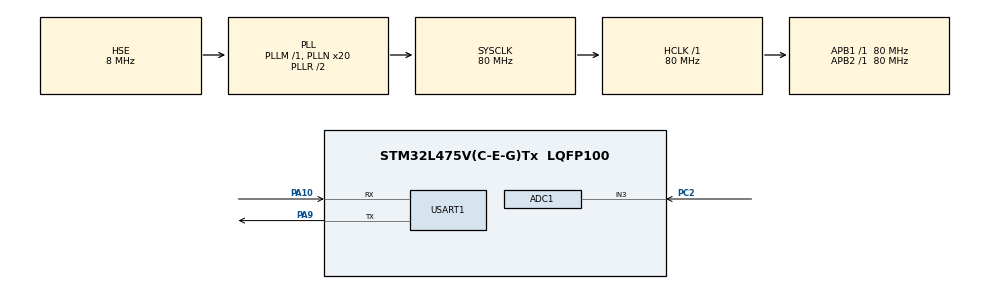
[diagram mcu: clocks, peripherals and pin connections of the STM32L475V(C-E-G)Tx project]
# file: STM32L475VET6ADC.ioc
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ADC1.Channel-1\#ChannelRegularConversion=ADC_CHANNEL_3
ADC1.ClockPrescaler=ADC_CLOCK_SYNC_PCLK_DIV2
ADC1.ContinuousConvMode=ENABLE
ADC1.EnableInjectedConversion=ENABLE
ADC1.InjMonitoredBy-2\#ChannelInjectedConversion=__NULL
ADC1.InjNumberOfConversion=1
ADC1.InjectedChannel-2\#ChannelInjectedConversion=ADC_CHANNEL_3
ADC1.InjectedOffsetNumber-2\#ChannelInjectedConversion=ADC_OFFSET_NONE
ADC1.InjectedRank-2\#ChannelInjectedConversion=1
ADC1.InjectedSamplingTime-2\#ChannelInjectedConversion=ADC_SAMPLETIME_2CYCLES_5
ADC1.NbrOfConversionFlag=1
ADC1.OffsetNumber-1\#ChannelRegularConversion=ADC_OFFSET_NONE
ADC1.Rank-1\#ChannelRegularConversion=1
ADC1.Rank1_Channel=ADC_CHANNEL_3
ADC1.SamplingTime-1\#ChannelRegularConversion=ADC_SAMPLETIME_2CYCLES_5
ADC1.master=1
Mcu.Family=STM32L4
Mcu.Name=STM32L475V(C-E-G)Tx
Mcu.Package=LQFP100
NVIC.ADC1_2_IRQn=true\:0\:0\:false\:false\:true\:true\:true\:true
NVIC.PriorityGroup=NVIC_PRIORITYGROUP_4
PA10.Mode=Asynchronous
PA10.Signal=USART1_RX
PA13\ (JTMS-SWDIO).Mode=Serial_Wire
PA13\ (JTMS-SWDIO).Signal=SYS_JTMS-SWDIO
PA14\ (JTCK-SWCLK).Mode=Serial_Wire
PA14\ (JTCK-SWCLK).Signal=SYS_JTCK-SWCLK
PA9.Mode=Asynchronous
PA9.Signal=USART1_TX
PC14-OSC32_IN\ (PC14).Mode=LSE-External-Oscillator
PC14-OSC32_IN\ (PC14).Signal=RCC_OSC32_IN
PC15-OSC32_OUT\ (PC15).Mode=LSE-External-Oscillator
PC15-OSC32_OUT\ (PC15).Signal=RCC_OSC32_OUT
PC2.Signal=ADCx_IN3
PH0-OSC_IN\ (PH0).Mode=HSE-External-Oscillator
PH0-OSC_IN\ (PH0).Signal=RCC_OSC_IN
PH1-OSC_OUT\ (PH1).Mode=HSE-External-Oscillator
PH1-OSC_OUT\ (PH1).Signal=RCC_OSC_OUT
ProjectManager.HeapSize=0x200
ProjectManager.StackSize=0x400
ProjectManager.TargetToolchain=MDK-ARM V5.32
RCC.ADCFreq_Value=64000000
RCC.AHBFreq_Value=80000000
RCC.APB1Freq_Value=80000000
RCC.APB1TimFreq_Value=80000000
RCC.APB2Freq_Value=80000000
RCC.APB2TimFreq_Value=80000000
RCC.CortexFreq_Value=80000000
RCC.HCLKFreq_Value=80000000
RCC.HSE_VALUE=8000000
RCC.HSI_VALUE=16000000
RCC.MSI_VALUE=4000000
RCC.PLLN=20
RCC.PLLSAI1N=16
RCC.PLLSourceVirtual=RCC_PLLSOURCE_HSE
RCC.SYSCLKFreq_VALUE=80000000
RCC.SYSCLKSource=RCC_SYSCLKSOURCE_PLLCLK
RCC.USBFreq_Value=64000000
RCC.VCOOutputFreq_Value=160000000
SH.ADCx_IN3.0=ADC1_IN3,IN3-Single-Ended
USART1.VirtualMode-Asynchronous=VM_ASYNC
board=custom

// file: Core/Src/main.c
/* USER CODE BEGIN Header */
/**
  ******************************************************************************
  * @file           : main.c
  * @brief          : Main program body
  ******************************************************************************
  * @attention
  *
  * Copyright (c) 2023 STMicroelectronics.
  * All rights reserved.
  *
  * This software is licensed under terms that can be found in the LICENSE file
  * in the root directory of this software component.
  * If no LICENSE file comes with this software, it is provided AS-IS.
  *
  ******************************************************************************
  */
/* USER CODE END Header */
#include "main.h"
#include "adc.h"
#include "usart.h"
#include "gpio.h"

/* USER CODE BEGIN Includes */
#include <stdio.h>

/* USER CODE END Includes */

/* USER CODE BEGIN PV */

uint16_t ADC_value;

/* USER CODE END PV */

void SystemClock_Config(void);

/* USER CODE BEGIN 0 */

//include <stdio.h>
int fputc(int ch, FILE *f)
{
	uint8_t temp[1] = {ch};
	HAL_UART_Transmit(&huart1, temp, 1, 1);

}

/* USER CODE END 0 */

int main(void)
{

  /* MCU Configuration--------------------------------------------------------*/

  /* Reset of all peripherals, Initializes the Flash interface and the Systick. */
  HAL_Init();

  /* Configure the system clock */
  SystemClock_Config();

  /* Initialize all configured peripherals */
  MX_GPIO_Init();
  MX_ADC1_Init();
  MX_USART1_UART_Init();
  /* USER CODE BEGIN 2 */
  HAL_ADCEx_Calibration_Start(&hadc1,ADC_SINGLE_ENDED);
  printf("System working!!!\r\n");
  /* USER CODE END 2 */

  /* Infinite loop */
  while (1)
  {
	  HAL_ADC_Start(&hadc1);
	  HAL_ADC_PollForConversion(&hadc1,50);

	  if(HAL_IS_BIT_SET(HAL_ADC_GetState(&hadc1), HAL_ADC_STATE_REG_EOC))
	  {
		ADC_value = HAL_ADC_GetValue(&hadc1);
		printf("The ADC value is %d \r\n", ADC_value);
		printf("The value of voltage is %.5f V\r\n", ADC_value*3.3f/4096);
		printf(" \r\n");
	  }
	  HAL_ADC_Stop(&hadc1);
	  HAL_Delay(2000);

	  printf("adc working !!!\r\n");

  }
}

void SystemClock_Config(void)
{
  RCC_OscInitTypeDef RCC_OscInitStruct = {0};
  RCC_ClkInitTypeDef RCC_ClkInitStruct = {0};

  /** Configure the main internal regulator output voltage
  */
  if (HAL_PWREx_ControlVoltageScaling(PWR_REGULATOR_VOLTAGE_SCALE1) != HAL_OK)
  {
    Error_Handler();
  }

  /** Initializes the RCC Oscillators according to the specified parameters
  * in the RCC_OscInitTypeDef structure.
  */
  RCC_OscInitStruct.OscillatorType = RCC_OSCILLATORTYPE_HSE;
  RCC_OscInitStruct.HSEState = RCC_HSE_ON;
  RCC_OscInitStruct.PLL.PLLState = RCC_PLL_ON;
  RCC_OscInitStruct.PLL.PLLSource = RCC_PLLSOURCE_HSE;
  RCC_OscInitStruct.PLL.PLLM = 1;
  RCC_OscInitStruct.PLL.PLLN = 20;
  RCC_OscInitStruct.PLL.PLLP = RCC_PLLP_DIV7;
  RCC_OscInitStruct.PLL.PLLQ = RCC_PLLQ_DIV2;
  RCC_OscInitStruct.PLL.PLLR = RCC_PLLR_DIV2;
  if (HAL_RCC_OscConfig(&RCC_OscInitStruct) != HAL_OK)
  {
    Error_Handler();
  }

  /** Initializes the CPU, AHB and APB buses clocks
  */
  RCC_ClkInitStruct.ClockType = RCC_CLOCKTYPE_HCLK|RCC_CLOCKTYPE_SYSCLK
                              |RCC_CLOCKTYPE_PCLK1|RCC_CLOCKTYPE_PCLK2;
  RCC_ClkInitStruct.SYSCLKSource = RCC_SYSCLKSOURCE_PLLCLK;
  RCC_ClkInitStruct.AHBCLKDivider = RCC_SYSCLK_DIV1;
  RCC_ClkInitStruct.APB1CLKDivider = RCC_HCLK_DIV1;
  RCC_ClkInitStruct.APB2CLKDivider = RCC_HCLK_DIV1;

  if (HAL_RCC_ClockConfig(&RCC_ClkInitStruct, FLASH_LATENCY_4) != HAL_OK)
  {
    Error_Handler();
  }
}

void Error_Handler(void)
{
  __disable_irq();
  while (1)
  {
  }
}
